AUTOSAR XML (schema 314)
package /ComponentType
  internal behavior Sa_CtrlTemp_InternalBehavior: component=Sa_CtrlTemp
    timing event CtrlTemp_Init1_InitEvent: start-on-event=CtrlTemp_Init1, period=0
    timing event TMT_CtrlTemp_Per1: start-on-event=CtrlTemp_Per1, period=0.002
    timing event TMT_CtrlTemp_Per2: start-on-event=CtrlTemp_Per2, period=0.1
    port-api-options:
      enable-take-address=false, indirect-api=false, port=AmbTemp
      enable-take-address=false, indirect-api=false, port=CtrlTemp_Per2_CP0
      enable-take-address=false, indirect-api=false, port=DiagStsTempRdPrf
      enable-take-address=false, indirect-api=false, port=FiltMeasTemp
      enable-take-address=false, indirect-api=false, port=NxtrDiagMgr
      enable-take-address=false, indirect-api=false, port=TemperatureADC
    runnable CtrlTemp_Init1
      data read access READ_TemperatureADC_Volt_f32: data-element=TemperatureADC.Volt_f32
      data write access WRITE_FiltMeasTemp_DegC_f32: data-element=FiltMeasTemp.DegC_f32
    runnable CtrlTemp_Per1
      data read access READ_DiagStsTempRdPrf_Cnt_lgc: data-element=DiagStsTempRdPrf.Cnt_lgc
      data read access READ_TemperatureADC_Volt_f32: data-element=TemperatureADC.Volt_f32
      data write access WRITE_FiltMeasTemp_DegC_f32: data-element=FiltMeasTemp.DegC_f32
    runnable CtrlTemp_Per2
      data read access READ_AmbTemp_DegC_f32: data-element=AmbTemp.DegC_f32
      sync call SC_CtrlTemp_Per2_CP0_CheckpointReached: operation=CtrlTemp_Per2_CP0.CheckpointReached, timeout=0
      sync call SC_NxtrDiagMgr_SetNTCStatus: operation=NxtrDiagMgr.SetNTCStatus, timeout=0
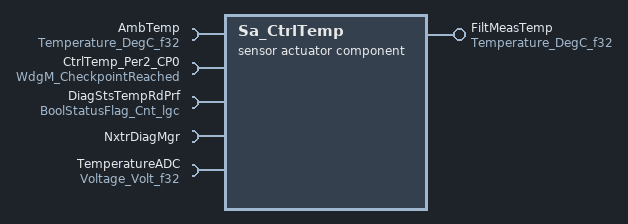
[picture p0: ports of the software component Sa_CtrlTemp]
  sensor actuator software component type Sa_CtrlTemp
    provide port FiltMeasTemp: unqueued-sender-com-spec{data-element=DegC_f32, can-invalidate=false, init-value=D_ZERO_ULS_F32}, provided-interface=Temperature_DegC_f32
    5 x require port:
      AmbTemp: unqueued-receiver-com-spec{data-element=DegC_f32, init-value=D_ZERO_ULS_F32}, required-interface=Temperature_DegC_f32
      CtrlTemp_Per2_CP0: client-com-spec=CheckpointReached, required-interface=WdgM_CheckpointReached
      DiagStsTempRdPrf: unqueued-receiver-com-spec{data-element=Cnt_lgc, init-value=D_FALSE_CNT_LGC}, required-interface=BoolStatusFlag_Cnt_lgc
      NxtrDiagMgr: required-com-specs=[GetNTCActive, GetNTCFailed, GetNTCStatus, SetNTCStatus], required-interface=NxtrDiagMgr
      TemperatureADC: unqueued-receiver-com-spec{data-element=Volt_f32, init-value=D_ZERO_ULS_F32}, required-interface=Voltage_Volt_f32
  swc implementation Sa_CtrlTemp_Implementation: behavior=Sa_CtrlTemp_InternalBehavior
    code-descriptors:
      code Code: type=SRC
